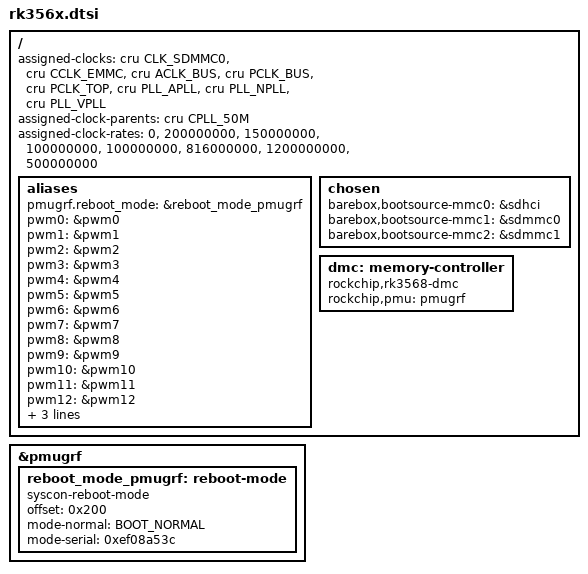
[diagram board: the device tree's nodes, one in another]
// SPDX-License-Identifier: (GPL-2.0+ OR MIT)

#include <dt-bindings/soc/rockchip,boot-mode.h>

/ {
	assigned-clocks =
		<&cru CLK_SDMMC0>,
		<&cru CCLK_EMMC>,
		<&cru ACLK_BUS>,
		<&cru PCLK_BUS>,
		<&cru PCLK_TOP>,
		<&cru PLL_APLL>,
		<&cru PLL_NPLL>,
		<&cru PLL_VPLL>;
	assigned-clock-parents =
		<&cru CPLL_50M>;
	assigned-clock-rates =
		<0>,
		<200000000>,
		<150000000>,
		<100000000>,
		<100000000>,
		<816000000>,
		<1200000000>,
		<500000000>;

	aliases {
		pmugrf.reboot_mode = &reboot_mode_pmugrf;
		pwm0 = &pwm0;
		pwm1 = &pwm1;
		pwm2 = &pwm2;
		pwm3 = &pwm3;
		pwm4 = &pwm4;
		pwm5 = &pwm5;
		pwm6 = &pwm6;
		pwm7 = &pwm7;
		pwm8 = &pwm8;
		pwm9 = &pwm9;
		pwm10 = &pwm10;
		pwm11 = &pwm11;
		pwm12 = &pwm12;
		pwm13 = &pwm13;
		pwm14 = &pwm14;
		pwm15 = &pwm15;
	};

	chosen {
		barebox,bootsource-mmc0 = &sdhci;
		barebox,bootsource-mmc1 = &sdmmc0;
		barebox,bootsource-mmc2 = &sdmmc1;
	};

	dmc: memory-controller {
		compatible = "rockchip,rk3568-dmc";
		rockchip,pmu = <&pmugrf>;
	};
};

&pmugrf {
	reboot_mode_pmugrf: reboot-mode {
		compatible = "syscon-reboot-mode";
		offset = <0x200>;
		mode-normal = <BOOT_NORMAL>;
		mode-serial = <0xef08a53c>; /* rk-usb-loader */
	};
};
